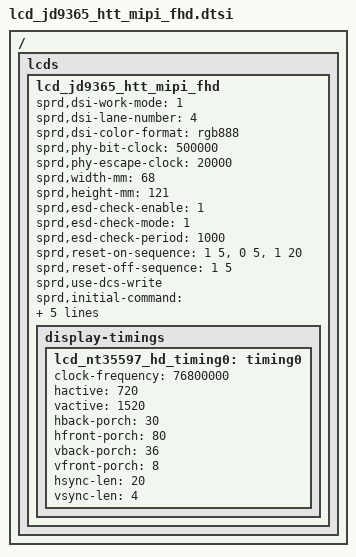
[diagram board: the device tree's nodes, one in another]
/*
 * GD9365 HTT LCD config dtsi file for spreadtrum
 *
 * Copyright (C) 2020, Spreadtrum Communications Inc.
 *
 * SPDX-License-Identifier: (GPL-2.0+ OR MIT)
 */

/ { lcds {
	lcd_jd9365_htt_mipi_fhd: lcd_jd9365_htt_mipi_fhd {

		sprd,dsi-work-mode = <1>; /* video burst mode*/
		sprd,dsi-lane-number = <4>;
		sprd,dsi-color-format = "rgb888";

		sprd,phy-bit-clock = <500000>;	/* kbps */
		sprd,phy-escape-clock = <20000>;/* kHz */

		sprd,width-mm = <68>;
		sprd,height-mm = <121>;

		sprd,esd-check-enable = <1>;
		sprd,esd-check-mode = <1>;
		sprd,esd-check-period = <1000>;

		sprd,reset-on-sequence = <1 5>, <0 5>, <1 20>;
		sprd,reset-off-sequence = <1 5>;

		sprd,use-dcs-write;

		sprd,initial-command = [
			23 00 00 02 E0 00
			23 00 00 02 E1 93
			23 00 00 02 E2 65
			23 00 00 02 E3 F8
			23 00 00 02 80 03
			23 00 00 02 E0 01
			23 00 00 02 00 00
			23 00 00 02 01 44
			23 00 00 02 03 00
			23 00 00 02 04 44
			23 00 00 02 17 00
			23 00 00 02 18 E7
			23 00 00 02 19 00
			23 00 00 02 1A 00
			23 00 00 02 1B E7
			23 00 00 02 1C 00
			23 00 00 02 24 FE
			23 00 00 02 25 20
			23 00 00 02 37 08
			23 00 00 02 38 04
			23 00 00 02 39 00
			23 00 00 02 3A 01
			23 00 00 02 3C 64
			23 00 00 02 3D FF
			23 00 00 02 3E FF
			23 00 00 02 3F FF
			23 00 00 02 40 04
			23 00 00 02 41 BE
			23 00 00 02 42 68
			23 00 00 02 43 18
			23 00 00 02 44 10
			23 00 00 02 45 32
			23 00 00 02 55 0F
			23 00 00 02 56 01
			23 00 00 02 57 66
			23 00 00 02 58 0A
			23 00 00 02 59 0A
			23 00 00 02 5A 28
			23 00 00 02 5B 10
			23 00 00 02 5C 15
			23 00 00 02 5D 7F
			23 00 00 02 5E 60
			23 00 00 02 5F 4D
			23 00 00 02 60 3F
			23 00 00 02 61 3A
			23 00 00 02 62 2A
			23 00 00 02 63 30
			23 00 00 02 64 1C
			23 00 00 02 65 39
			23 00 00 02 66 3B
			23 00 00 02 67 3E
			23 00 00 02 68 5D
			23 00 00 02 69 4B
			23 00 00 02 6A 53
			23 00 00 02 6B 45
			23 00 00 02 6C 42
			23 00 00 02 6D 36
			23 00 00 02 6E 26
			23 00 00 02 6F 12
			23 00 00 02 70 7F
			23 00 00 02 71 60
			23 00 00 02 72 4D
			23 00 00 02 73 3F
			23 00 00 02 74 3A
			23 00 00 02 75 2A
			23 00 00 02 76 30
			23 00 00 02 77 1C
			23 00 00 02 78 39
			23 00 00 02 79 3B
			23 00 00 02 7A 3E
			23 00 00 02 7B 5D
			23 00 00 02 7C 4B
			23 00 00 02 7D 53
			23 00 00 02 7E 45
			23 00 00 02 7F 42
			23 00 00 02 80 36
			23 00 00 02 81 26
			23 00 00 02 82 12
			23 00 00 02 E0 02
			23 00 00 02 00 50
			23 00 00 02 01 5E
			23 00 00 02 02 5F
			23 00 00 02 03 5F
			23 00 00 02 04 4A
			23 00 00 02 05 48
			23 00 00 02 06 46
			23 00 00 02 07 44
			23 00 00 02 08 40
			23 00 00 02 09 5F
			23 00 00 02 0A 5F
			23 00 00 02 0B 5F
			23 00 00 02 0C 5F
			23 00 00 02 0D 5F
			23 00 00 02 0E 5F
			23 00 00 02 0F 5F
			23 00 00 02 10 5F
			23 00 00 02 11 5F
			23 00 00 02 12 5F
			23 00 00 02 13 5F
			23 00 00 02 14 5F
			23 00 00 02 15 5F
			23 00 00 02 16 51
			23 00 00 02 17 5E
			23 00 00 02 18 5F
			23 00 00 02 19 5F
			23 00 00 02 1A 4B
			23 00 00 02 1B 49
			23 00 00 02 1C 47
			23 00 00 02 1D 45
			23 00 00 02 1E 41
			23 00 00 02 1F 5F
			23 00 00 02 20 5F
			23 00 00 02 21 5F
			23 00 00 02 22 5F
			23 00 00 02 23 5F
			23 00 00 02 24 5F
			23 00 00 02 25 5F
			23 00 00 02 26 5F
			23 00 00 02 27 5F
			23 00 00 02 28 5F
			23 00 00 02 29 5F
			23 00 00 02 2A 5F
			23 00 00 02 2B 5F
			23 00 00 02 2C 01
			23 00 00 02 2D 1F
			23 00 00 02 2E 1E
			23 00 00 02 2F 1F
			23 00 00 02 30 05
			23 00 00 02 31 07
			23 00 00 02 32 09
			23 00 00 02 33 0B
			23 00 00 02 34 11
			23 00 00 02 35 1F
			23 00 00 02 36 1F
			23 00 00 02 37 1F
			23 00 00 02 38 1F
			23 00 00 02 39 1F
			23 00 00 02 3A 1F
			23 00 00 02 3B 1F
			23 00 00 02 3C 1F
			23 00 00 02 3D 1F
			23 00 00 02 3E 1F
			23 00 00 02 3F 1F
			23 00 00 02 40 1F
			23 00 00 02 41 1F
			23 00 00 02 42 00
			23 00 00 02 43 1F
			23 00 00 02 44 1E
			23 00 00 02 45 1F
			23 00 00 02 46 04
			23 00 00 02 47 06
			23 00 00 02 48 08
			23 00 00 02 49 0A
			23 00 00 02 4A 10
			23 00 00 02 4B 1F
			23 00 00 02 4C 1F
			23 00 00 02 4D 1F
			23 00 00 02 4E 1F
			23 00 00 02 4F 1F
			23 00 00 02 50 1F
			23 00 00 02 51 1F
			23 00 00 02 52 1F
			23 00 00 02 53 1F
			23 00 00 02 54 1F
			23 00 00 02 55 1F
			23 00 00 02 56 1F
			23 00 00 02 57 1F
			23 00 00 02 58 40
			23 00 00 02 59 00
			23 00 00 02 5A 00
			23 00 00 02 5B 10
			23 00 00 02 5C 09
			23 00 00 02 5D 70
			23 00 00 02 5E 01
			23 00 00 02 5F 02
			23 00 00 02 60 40
			23 00 00 02 61 01
			23 00 00 02 62 02
			23 00 00 02 63 54
			23 00 00 02 64 54
			23 00 00 02 65 55
			23 00 00 02 66 FF
			23 00 00 02 67 74
			23 00 00 02 68 0D
			23 00 00 02 69 54
			23 00 00 02 6A 54
			23 00 00 02 6B 18
			23 00 00 02 6C 00
			23 00 00 02 6D 00
			23 00 00 02 6E 00
			23 00 00 02 6F 80
			23 00 00 02 E0 04
			23 00 00 02 09 10
			23 00 00 02 0E 4A
			23 00 00 02 96 0A
			23 00 00 02 E0 00
			23 00 00 02 E6 02
			23 00 00 02 E7 02
			15 00 00 02 35 00
			13 78 00 01 11
			13 64 00 01 29
			];

		sprd,sleep-in-command = [
			13 0A 00 01 28
			13 78 00 01 10
			23 00 00 02 4F 01
			];

		sprd,sleep-out-command = [
			13 78 00 01 11
			13 64 00 01 29
			];

		display-timings {
			lcd_nt35597_hd_timing0: timing0 {
				clock-frequency = <76800000>;
				hactive = <720>;
				vactive = <1520>;
				hback-porch = <30>;
				hfront-porch = <80>;
				vback-porch = <36>;
				vfront-porch = <8>;
				hsync-len = <20>;
				vsync-len = <4>;
			};
		};
	};
};};
